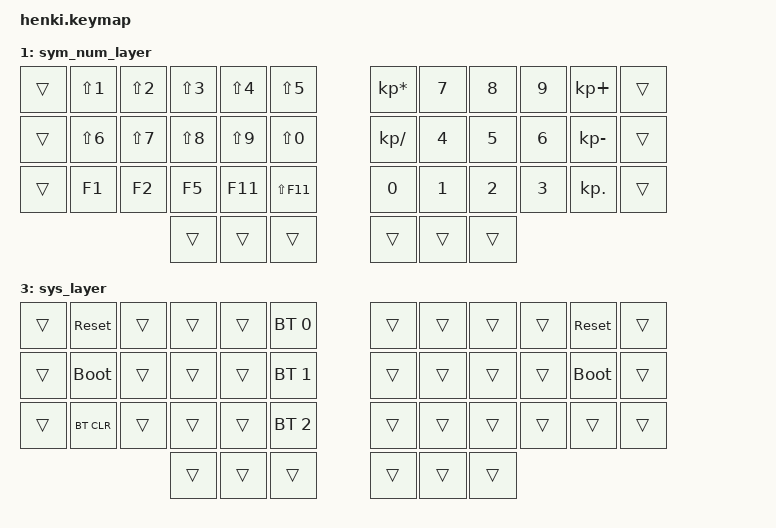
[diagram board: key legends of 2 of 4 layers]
// Copyright (c) 2022 The ZMK Contributors
// SPDX-License-Identifier: MIT

#include <behaviors.dtsi>
#include <dt-bindings/zmk/keys.h>
#include <dt-bindings/zmk/bt.h>
//add mouse for wheel
#include <dt-bindings/zmk/pointing.h>

#define HRML(k1,k2,k3,k4) &ht LGUI k1  &ht LALT k2  &ht LCTRL k3  &ht LSHFT k4
#define HRMR(k1,k2,k3,k4) &ht RSHFT k1  &ht RCTRL k2  &ht RALT k3  &ht RGUI k4
#define TASK_V &kp LG(TAB)
#define DESK_P &kp LG(LC(LEFT))
#define DESK_N &kp LG(LC(RIGHT))
#define CLANG_W &kp LA(LSHFT)

#define COMBO(NAME, BINDINGS, KEYPOS, LAYERS) \
    combo_##NAME { \
        timeout-ms = <50>; \
        bindings = <BINDINGS>; \
        key-positions = <KEYPOS>; \
        layers = <LAYERS>; \
    };

/ {
    behaviors {
        ht: hold_tap {
            label = "hold_tap";
            compatible = "zmk,behavior-hold-tap";
            #binding-cells = <2>;
            flavor = "tap-preferred";
            //flavor = "balanced";
            tapping-term-ms = <200>;
            quick-tap-ms = <250>;
            //retro-tap;
            bindings = <&kp>, <&kp>;
        };
        tt: thumb_hold_tap {
            label = "thumb_hold_tap";
            compatible = "zmk,behavior-hold-tap";
            #binding-cells = <2>;
            flavor = "tap-preferred";
            tapping_term_ms = <200>;
            quick_tap_ms = <250>;
            bindings = <&mo>, <&kp>;
        };
    };

    conditional_layers {
        compatible = "zmk,conditional-layers";
       adjust_layer {
            if-layers = <1 2>;
            then-layer = <3>;
        };
    };

        //╭──────╭──────┬──────┬──────┬──────┬──────╮   ╭──────┬──────┬──────┬──────┬──────╮──────╮
        //│  0   │  1   │  2   │  3   │  4   │  5   │   │  6   │  7   │  8   │  9   │  10  │  11  │
        //├──────├──────┼──────┼──────┼──────┼──────┤   ├──────┼──────┼──────┼──────┼──────┤──────┤
        //│  12  │  13  │  14  │  15  │  16  │  17  │   │  18  │  19  │  20  │  21  │  22  │  23  │
        //├──────├──────┼──────┼──────┼──────┼──────┤   ├──────┼──────┼──────┼──────┼──────┤──────┤
        //│  24  │  25  │  26  │  27  │  28  │  29  │   │  30  │  31  │  32  │  33  │  34  │  35  │
        //╰──────╰──────┴──────┼──────┼──────┼──────┤   ├──────┼──────┼──────┼──────┴──────╯──────╯
        //                     |  36  |  37  |  38  |   |  39  |  40  |  41  |
        //                     ╰──────┴──────┴──────╯   ╰──────┴──────┴──────╯

    combos {
        compatible = "zmk,combos";
    
        COMBO(RBKT,    &kp RBKT,    1 2,     0)
        COMBO(GRAVE,   &kp GRAVE,   13 14,    0)
        COMBO(BSLH,    &kp BSLH,    25 26,    0)
        
        COMBO(LBKT,    &kp LBKT,    9 10,    0)
        COMBO(SQT,     &kp SQT,     21 22,    0)
        COMBO(MINUS,   &kp MINUS,   33 34,    0)
        
        COMBO(EQUAL,   &kp EQUAL,   18 19,    1)

        COMBO(ChangeL, CLANG_W,     30 31,    1)

    };

    keymap {
        compatible = "zmk,keymap";

        // - 0
        default_layer {
            bindings = <
        //╭──────────╭──────────┬──────────┬──────────┬──────────┬──────────╮   ╭──────────┬──────────┬──────────┬──────────┬──────────╮──────────╮
        //│ [        │ Q        │ W        │ E        │ R        │ T        │   │ Y        │ U        │ I        │ O        │ P        │ ]        │
            &kp LBKT   &kp Q      &kp W      &kp E      &kp R      &kp T          &kp Y      &kp U      &kp I      &kp O      &kp P      &kp RBKT
        //├──────────├──────────┼──────────┼──────────┼──────────┼──────────┤   ├──────────┼──────────┼──────────┼──────────┼──────────┤──────────┤
        //│ `        │ A        │  S       │  D       │  F       │ G        │   │ H        │ J        │  K       │ L        │ ;        │ '        │
            &kp GRAVE  HRML(A,     S,         D,         F)         &kp G          &kp H     HRMR(J,     K,        L,         SEMI)      &kp SQT
        //├──────────├──────────┼──────────┼──────────┼──────────┼──────────┤   ├──────────┼──────────┼──────────┼──────────┼──────────┤──────────┤
        //│ |        │ Z        │  X       │  C       │  V       │  B       │   │  N       │  M       │ , <      │ . >      │ / ?      │  \       │
            &kp PIPE   &kp Z      &kp X      &kp C      &kp V      &kp B          &kp N      &kp M      &kp COMMA  &kp DOT    &kp FSLH   &kp BSLH
        //╰──────────╰──────────┴──────────┴──────────┼──────────┼──────────┤   ├──────────┼──────────┼──────────┴──────────┴──────────╯──────────╯
                 &tt 2 TAB          &mt LSHFT SPACE         &tt 1 RET                  &tt 1 ESC            &mt RSHFT BSPC          &tt 2 DEL
        //╰─────────────────────┴─────────────────────┴─────────────────────╯   ╰─────────────────────┴─────────────────────┴─────────────────────╯
            >;
        };

        // - 1
        sym_num_layer {
            bindings = <
        //╭──────────╭──────────┬──────────┬──────────┬──────────┬──────────╮   ╭──────────┬──────────┬──────────┬──────────┬──────────╮──────────╮
        //│          │ !/!      │ @/"      │ #/№      │ $/;      │ %/%      │   │ NUM_*    │ 7        │ 8        │ 9        │ NUM_+    │          │
            &trans     &kp LS(N1) &kp LS(N2) &kp LS(N3) &kp LS(N4) &kp LS(N5)   &kp KP_MULTIPLY &kp N7  &kp N8     &kp N9     &kp KP_PLUS &trans
        //├──────────├──────────┼──────────┼──────────┼──────────┼──────────┤   ├──────────┼──────────┼──────────┼──────────┼──────────┤──────────┤
        //│          │ ^/:      │ &/?      │ */*      │ (/(      │ )/)      │   │ NUM_/    │ 4        │ 5        │ 6        │ NUM_-    │          │
            &trans     &kp LS(N6) &kp LS(N7) &kp LS(N8) &kp LS(N9) &kp LS(N0)   &kp KP_DIVIDE &kp N4    &kp N5     &kp N6     &kp KP_MINUS &trans
        //├──────────├──────────┼──────────┼──────────┼──────────┼──────────┤   ├──────────┼──────────┼──────────┼──────────┼──────────┤──────────┤
        //│          │ F1       │ F2       │ F5       │ F11      │Shift+F11 │   │ 0        │ 1        │ 2        │ 3        │ NUM_.    │          │
            &trans     &kp F1     &kp F2     &kp F5     &kp F11   &kp LS(F11)     &kp N0     &kp N1     &kp N2     &kp N3     &kp KP_DOT &trans
        //╰──────────╰──────────┴──────────┴──────────┼──────────┼──────────┤   ├──────────┼──────────┼──────────┴──────────┴──────────╯──────────╯
                                             &trans     &trans     &trans         &trans     &trans     &trans
        //                                 ╰──────────┴──────────┴──────────╯   ╰──────────┴──────────┴──────────╯
            >;
        };

        // - 2
        num_nav_layer {
            bindings = <
        //╭──────────╭──────────┬──────────┬──────────┬──────────┬──────────╮   ╭──────────┬──────────┬──────────┬──────────┬──────────╮──────────╮
        //│          │ NUM_*    │ 7        │ 8        │ 9        │ NUM_+    │   │ SCRL_UP  │ HOME     │ C_PLAY   │ PG_UP    │ C_VOL_UP │          │
            &trans   &kp KP_MULTIPLY &kp N7  &kp N8     &kp N9     &kp KP_PLUS  &msc SCRL_UP &kp HOME   &kp C_PLAY &kp PG_UP &kp C_VOL_UP &trans
        //├──────────├──────────┼──────────┼──────────┼──────────┼──────────┤   ├──────────┼──────────┼──────────┼──────────┼──────────┤──────────┤
        //│          │ NUM_/    │ 4        │ 5        │ 6        │ NUM_-    │   │ LEFT     │ DOWN     │ UP       │ RIGHT    │ C_VOL_DN │          │
              &trans  HRML(KP_DIVIDE, N4,    N5,          N6)    &kp KP_MINUS     &kp LEFT   &kp DOWN   &kp UP     &kp RIGHT &kp C_VOL_DN &trans
        //├──────────├──────────┼──────────┼──────────┼──────────┼──────────┤   ├──────────┼──────────┼──────────┼──────────┼──────────┤──────────┤
        //│          │ 0        │ 1        │ 2        │ 3        │ NUM_.    │   │ SCRL_DOWN│ END      │ PSCRN    │ PG_DOWN  │ C_MUTE   │          │
            &trans     &kp N0     &kp N1     &kp N2     &kp N4     &kp KP_DOT   &msc SCRL_DOWN &kp END  &kp PSCRN  &kp PG_DN  &kp C_MUTE &trans
        //╰──────────╰──────────┴──────────┴──────────┼──────────┼──────────┤   ├──────────┼──────────┼──────────┴──────────┴──────────╯──────────╯
                                             &trans     &trans     &trans         &trans     &trans     &trans
        //                                 ╰──────────┴──────────┴──────────╯   ╰──────────┴──────────┴──────────╯
            >;
        };

        // - 3
        sys_layer {
            bindings = <
        //╭──────────╭──────────┬──────────┬──────────┬──────────┬──────────╮   ╭──────────┬──────────┬──────────┬──────────┬──────────╮──────────╮
        //│          │  RESET   │          │          │          │PROFILE 0 │   │          │          │          │          │  RESET   │          │
            &trans    &sys_reset  &trans     &trans     &trans    &bt BT_SEL 0    &trans     &trans     &trans     &trans    &sys_reset  &trans
        //├──────────├──────────┼──────────┼──────────┼──────────┼──────────┤   ├──────────┼──────────┼──────────┼──────────┼──────────┤──────────┤
        //│          │BOOTLOADER│          │          │          │PROFILE 1 │   │          │          │          │          │BOOTLOADER│          │
            &trans   &bootloader  &trans     &trans     &trans    &bt BT_SEL 1    &trans     &trans     &trans     &trans    &bootloader &trans
        //├──────────├──────────┼──────────┼──────────┼──────────┼──────────┤   ├──────────┼──────────┼──────────┼──────────┼──────────┤──────────┤
        //│          │ CLEAR BT │          │          │          │PROFILE 2 │   │          │          │          │          │          │          │
            &trans     &bt BT_CLR  &trans     &trans    &trans    &bt BT_SEL 2    &trans     &trans     &trans     &trans     &trans     &trans
        //╰──────────╰──────────┴──────────┴──────────┼──────────┼──────────┤   ├──────────┼──────────┼──────────┴──────────┴──────────╯──────────╯
                                              &trans     &trans     &trans         &trans     &trans     &trans
        //                                 ╰──────────┴──────────┴──────────╯   ╰──────────┴──────────┴──────────╯
            >;
        };
    };
};
